AUTOSAR XML (schema 00052)
package /apd/AdaptiveApplicationSwComponentTypes
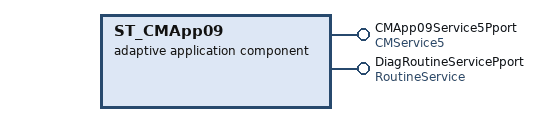
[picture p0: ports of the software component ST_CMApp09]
  adaptive application sw component type ST_CMApp09
    provide port CMApp09Service5Pport: provided-interface=CMService5
    provide port DiagRoutineServicePport: provided-interface=RoutineService
package /apd/Executables
  executable ST_CMApp09: category=APPLICATION_LEVEL, minimum-timer-granularity=1000.0
    root sw component prototype ST_CMApp09Root: application-type=ST_CMApp09
